# cslr_tmr_001 register map
Vendor: Texas Instruments
Peripheral module from a debugger description file.
Registers are 32-bit, read-write, reset 0x0 unless marked. A register's access mark holds for its fields unless they carry their own. Offsets are as the file gives them; lines under a group give offsets from that group; [hi:lo] are bit positions; {n}, {i} and the like mark numbered series; 'fields as' and 'values as' point back to an identical list; <NAME> marks a mode.

## TMR — TIMER
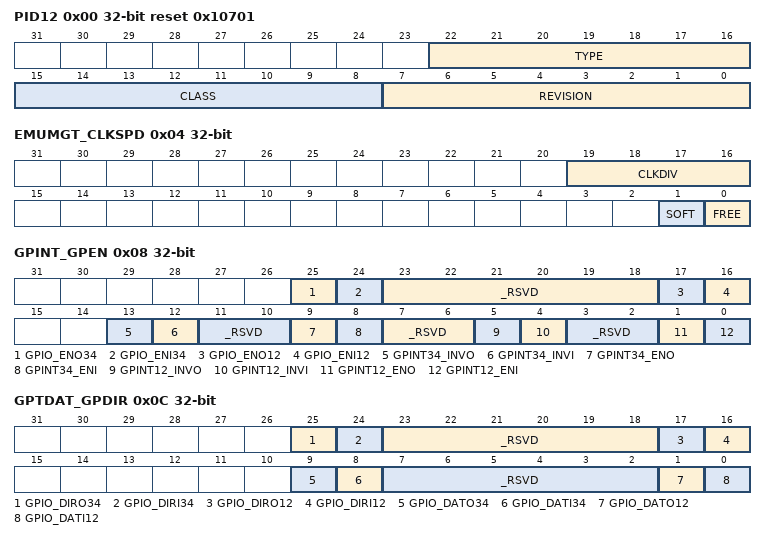
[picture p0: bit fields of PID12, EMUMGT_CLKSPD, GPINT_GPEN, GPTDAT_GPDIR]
0x00 PID12 access not given reset 0x10701 — Peripheral ID Register
  [22:16] TYPE ro — Type of Peripheral
  [15:8] CLASS ro — Class of Peripheral
  [7:0] REVISION ro — Revision level of the timer
0x04 EMUMGT_CLKSPD access not given (reset mask 0xFFF00003) — Emulation Management/Clock Speed Registers
  [19:16] CLKDIV ro — Divided by CPU and VBUS Clock Speed Ratios.
  [1] SOFT rw — Determines emulation mode functionality of the timer. When FREE bit is cleared, the soft bit selects the timer mode. SOFT=0, timers stops immediately. SOFT=1, timer stops when the counter increments and reaches the value in the timer period register.
    0=OFF; 1=ON
  [0] FREE rw — Determines emulation mode functionality of the timer. When the FREE bit is cleared, the soft bit selects the timer mode. FREE=0, the soft bit selects the timer mode. FREE=1, the timer runs free regardless of the soft bit.
    0=ON; 1=OFF
0x08 GPINT_GPEN access not given — GPIO IO Interrupt Control and Enable Registers
  [25] GPIO_ENO34 rw — Enable the timer output TOUTP34 in GPIO mode.
    0=TIMER_OUTPUT; 1=GPIO_PIN
  [24] GPIO_ENI34 rw — Enable the timer input TINP34 in GPIO mode.
    0=TIMER_INPUT; 1=GPIO_PIN
  [23:18] _RSVD — (access N)
  [17] GPIO_ENO12 rw — Enable the timer output TOUTP12 in GPIO mode.
    0=TIMER_OUTPUT; 1=GPIO_PIN
  [16] GPIO_ENI12 rw — Enable the timer input TINP12 in GPIO mode.
    0=TIMER_INPUT; 1=GPIO_PIN
  [13] GPINT34_INVO rw — Invert bit for timer output TOUTP34 when it is used to source an interrupt or event (GPINT34_ENO=1)
    0=DISABLE; 1=ENABLE
  [12] GPINT34_INVI rw — Invert bit for timer input TINP34 when it is used to source an interrupt or event (GPINT34_ENI=1).
    0=DISABLE; 1=ENABLE
  [11:10] _RSVD — (access N)
  [9] GPINT34_ENO rw — Enable the timer output TOUTP34 to source the interrupt or event in GPIO mode.
    0=DISABLE; 1=ENABLE
  [8] GPINT34_ENI rw — Enable the timer input TINP34 to source the interrupt or event in GPIO mode.
    0=DISABLE; 1=ENABLE
  [7:6] _RSVD — (access N)
  [5] GPINT12_INVO rw — Invert bit for timer output TOUTP12 when it is used to source an interrupt or event (GPINT12_ENO=1).
    0=DISABLE; 1=ENABLE
  [4] GPINT12_INVI rw — Invert bit for timer input TINP12 when it is used to source an interrupt or event (GPINT12_ENI=1)
    0=DISABLE; 1=ENABLE
  [3:2] _RSVD — (access N)
  [1] GPINT12_ENO rw — Enable the timer output TOUTP12 to source the interrupt or event in GPIO mode.
    0=DISABLE; 1=ENABLE
  [0] GPINT12_ENI rw — Enable the timer input TINP12 to source the interrupt or event in GPIO mode.
    0=DISABLE; 1=ENABLE
0x0C GPTDAT_GPDIR access not given — General Purpose IO Data and Direction registers
  [25] GPIO_DIRO34 rw — Controls the direction of the timer output TOUTP34 in GPIO mode
    0=TIMER_OUTPUT; 1=GPIO_PIN
  [24] GPIO_DIRI34 rw — Controls the direction of the timer input TINP34 in GPIO mode. It must be set to 0 to be used as input in GPIO interrupt mode.
    0=TIMER_INPUT; 1=GPIO_PIN
  [23:18] _RSVD — (access N)
  [17] GPIO_DIRO12 rw — Controls the direction of the timer output TOUTP12 in GPIO mode
    0=TIMER_OUTPUT; 1=GPIO_PIN
  [16] GPIO_DIRI12 rw — Controls the direction of the timer input TINP12 in GPIO mode. It must be set to 0 to be used as input in GPIO interrupt mode.
    0=TIMER_INPUT; 1=GPIO_PIN
  [9] GPIO_DATO34 rw — When GPIO_DIRI34=0: timer output TINP34 functions as a GPIO input, the logic value read in this bit is equal to the logic level present at the timer input. Writes to this bit have no effect. The GP input is sampled with the VBUS clock.
    0=DISABLE; 1=ENABLE
  [8] GPIO_DATI34 rw — When GPIO_DIRI34=0: timer input TINP34 functions as a GPIO input, the logic value read in this bit is equal to the logic level present at the timer input. Writes to this bit have no effect. The GP input is sampled with the VBUS clock.
    0=DISABLE; 1=ENABLE
  [7:2] _RSVD — (access N)
  [1] GPIO_DATO12 rw — When GPIO_DIRI34=0: timer output TINP12 functions as a GPIO output, the logic value read in this bit is equal to the logic level present at the timer input. Writes to this bit have no effect. The GP input is sampled with the VBUS clock.
    0=DISABLE; 1=ENABLE
  [0] GPIO_DATI12 rw — When GPIO_DIRI34=0: timer input TINP12 functions as a GPIO input, the logic value read in this bit is equal to the logic level present at the timer input. Writes to this bit have no effect. The GP input is sampled with the VBUS clock.
    0=DISABLE; 1=ENABLE
0x10 TIM12 — Timer Counter Register 12
  [31:0] CNT12
0x14 TIM34 — Timer Counter Register 34
  [31:0] CNT34
0x18 PRD12 — Timer Period Register 12
0x1C PRD34 — Timer Period Register 34
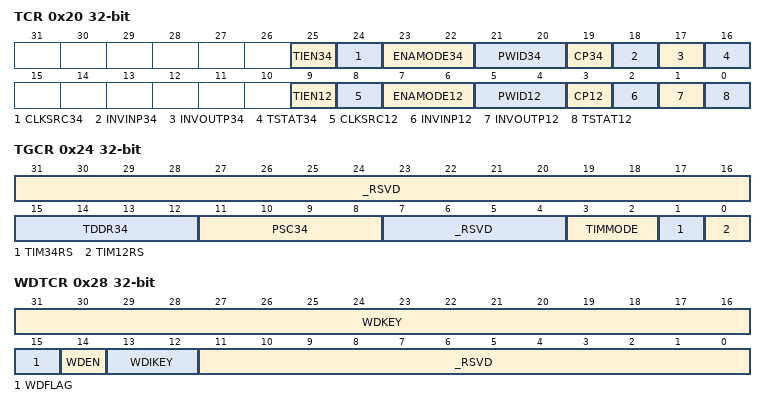
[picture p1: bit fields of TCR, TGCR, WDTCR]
0x20 TCR access per field — Timer Control Register
  [25] TIEN34 rw — TIEN determines if the timer clock is gated by the timer input. Applicable only when CLKSRC=0.
    0=NOT_GATED; 1=GATED_BY_TINP
  [24] CLKSRC34 rw — CLKSRC determines the selected clock source for the timer.
    0=VBUS; 1=INPUT_PIN
  [23:22] ENAMODE34 rw — Enabling mode: determines the enabling modes of the timer.
    0=DISABLED; 1=ONCE; 2=CONTINUOUS
  [21:20] PWID34 rw — PWID[1:0]: Pulse width. Only used in pulse mode (C/P_=0) by the timer controls the timer output.
    0=INACTIVE_1CYCLE; 1=INACTIVE_2CYCLES; 2=INACTIVE_3CYCLES; 3=INACTIVE_4CYCLES
  [19] CP34 rw — Clock/Pulse mode for timer output.
    0=PULSE_MODE; 1=CLOCK_MODE
  [18] INVINP34 rw — Timer input inverter control. Only affects operation if CLKSRC=1, Timer Input pin.
    0=DONT_INVERT_OUTPUT; 1=INVERT_OUTPUT
  [17] INVOUTP34 rw — Timer output inverter control.
    0=DONT_INVERT_OUTPUT; 1=INVERT_OUTPUT
  [16] TSTAT34 ro — TSTAT: timer status. Value of timer output. TSTATx drives the timer output pin when the pin is used as a timer pin (instead of a GPIO) and maybe inverted by setting INVOUTP=1.(TSTAT is read only)
    0=LOW; 1=HIGH
  [9] TIEN12 rw — TIEN determines if the timer clock is gated by the timer input. Applicable only when CLKSRC=0.
    0=NOT_GATED; 1=GATED_BY_TINP
  [8] CLKSRC12 rw — CLKSRC determines the selected clock source for the timer.
    0=VBUS; 1=INPUT_PIN
  [7:6] ENAMODE12 rw — Enabling mode: determines the enabling modes of the timer.
    0=DISABLED; 1=ONCE; 2=CONTINUOUS
  [5:4] PWID12 rw — PWID[1:0]: Pulse width. Only used in pulse mode (C/P_=0) by the timer controls the timer output.
    values as PWID34
  [3] CP12 rw — Clock/Pulse mode for timer output.
    0=PULSE_MODE; 1=CLOCK_MODE
  [2] INVINP12 rw — Timer input inverter control. Only affects operation if CLKSRC=1, Timer Input pin.
    0=DONT_INVERT_OUTPUT; 1=INVERT_OUTPUT
  [1] INVOUTP12 rw — Timer output inverter control.
    0=DONT_INVERT_OUTPUT; 1=INVERT_OUTPUT
  [0] TSTAT12 ro — TSTAT: timer status. Value of timer output. TSTATx drives the timer output pin when the pin is used as a timer pin (instead of a GPIO) and maybe inverted by setting INVOUTP=1.(TSTAT is read only)
    0=LOW; 1=HIGH
0x24 TGCR — Timer Global Control Register
  [31:16] _RSVD — This bits are not used
  [15:12] TDDR34 — Timer linear divide-down ratio specifies the timer divide-down for the timer TIM34. When the timer enabled, the TDDR34 increments every timer clock. The TIM34 counter (TIM3/TIM4) increments on the cycle after the TDDR34 matches the PSC34. The TDDR34 resets to zero and continues. When the TIM3/TIM4 matches the PRD3/PRD4, the TIM34 stops if it enabled one time or TIM3/TIM4 reset to zero on the cycle after matching the PRD3/PRD4 and TIM34 continues if the timer enabled continuously. V=0000.
  [11:8] PSC34 — TIM34 pre-scalar counter specifies the count for TIM34. DV=0000.
  [7:4] _RSVD — Bits not used
  [3:2] TIMMODE — TIMMODE determines timer modes. TIMMODE[1:0]=00: The timer is in 64-bit GP timer mode. (DV) TIMMODE[1:0]=01: The timer is in dual 32-bit timer, unchained mode. TIMMODE[1:0]=10: The timer is in 64-bit Watchdog timer mode. TIMMODE[1:0]=11: The timer is in dual 32-bit timer, chained mode.
    0=64BIT_GPTIM; 1=32BIT_DUAL; 2=64BIT_WDTIM; 3=32BIT_CHAINED
  [1] TIM34RS — TIM34RS_: timer TIM34 reset.
    0=IN_RESET; 1=NOT_IN_RESET
  [0] TIM12RS — TIM12RS_: timer TIM12 reset.
    0=IN_RESET; 1=NOT_IN_RESET
0x28 WDTCR — Watchdog Timer Control Register
  [31:16] WDKEY — 16-bit watchdog reset key, only the sequence of an A5C6h followed by a DA7Eh services the watchdog. Not applicable in regular timer mode. (DV=0's). See section 4 for more details.
    0xA5C6=PREACTIVE; 0xDA7E=ACTIVE
  [15] WDFLAG — Watchdog flag bit This bit can be cleared by enabling the watchdog timer, by device reset and by being written with '1'. It is set by a watchdog time-out.
    0=TIMEOUT; 1=NOTIMEOUT
  [14] WDEN — Watchdog timer enable bit
    0=DISABLE; 1=ENABLE
  [13:12] WDIKEY — 2-bit watchdog IDLE enable key, only the sequence of a 01b followed by a 10b enable the watchdog to go in IDLE mode. Not applicable in regular timer mode. (DV=0's). A write of 00b to the WDIKEY will disallow the watchdog timer goes into the IDLE mode.
    0=NO_IDLE; 1=GO_IDLE_START; 2=GO_IDLE
  [11:0] _RSVD — Bits not used
